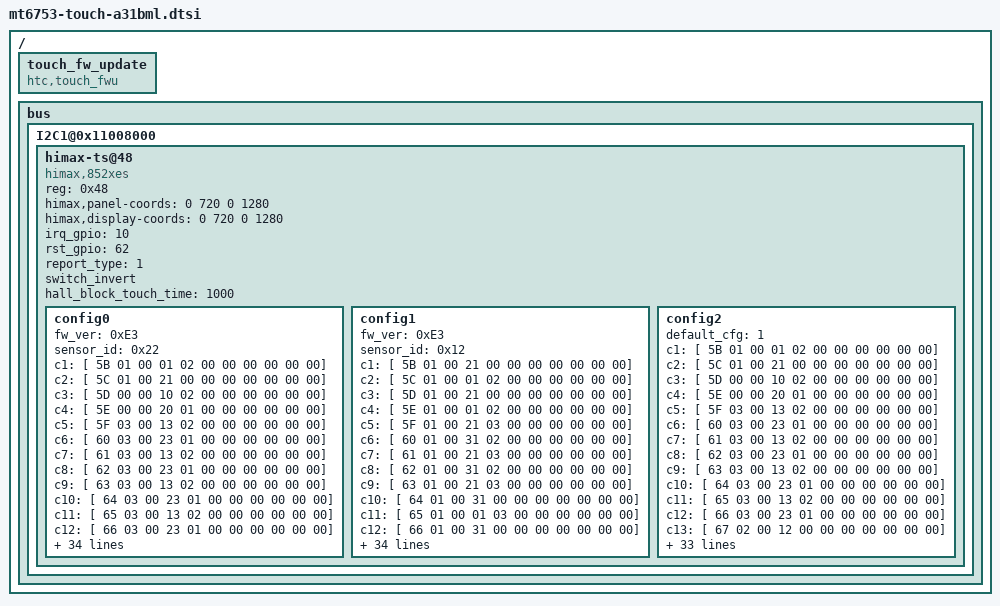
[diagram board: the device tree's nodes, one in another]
/{
	touch_fw_update {
		compatible = "htc,touch_fwu";
	};

	bus {
		I2C1@0x11008000 {

			status = "ok";
		himax-ts@48 {
			compatible               	= "himax,852xes";
			reg                      	= <0x48>;
				himax,panel-coords	= <0 720 0 1280>;
				himax,display-coords	= <0 720 0 1280>;
				irq_gpio = <10>;
				rst_gpio = <62>;
				report_type	= <1>;
				switch_invert;
				hall_block_touch_time	= <1000>;	/* msec */

			config0 {	//truly
				fw_ver     	= <0xE3>;
				sensor_id     	= <0x22>;
				c1 = [ 5B 01 00 01 02 00 00 00 00 00 00];
				c2 = [ 5C 01 00 21 00 00 00 00 00 00 00];
				c3 = [ 5D 00 00 10 02 00 00 00 00 00 00];
				c4 = [ 5E 00 00 20 01 00 00 00 00 00 00];
				c5 = [ 5F 03 00 13 02 00 00 00 00 00 00];
				c6 = [ 60 03 00 23 01 00 00 00 00 00 00];
				c7 = [ 61 03 00 13 02 00 00 00 00 00 00];
				c8 = [ 62 03 00 23 01 00 00 00 00 00 00];
				c9 = [ 63 03 00 13 02 00 00 00 00 00 00];
				c10 = [ 64 03 00 23 01 00 00 00 00 00 00];
				c11 = [ 65 03 00 13 02 00 00 00 00 00 00];
				c12 = [ 66 03 00 23 01 00 00 00 00 00 00];
				c13 = [ 67 02 00 12 00 00 00 00 00 00 00];
				c14 = [ 68 02 00 02 01 00 00 00 00 00 00];
				c15 = [ 69 02 00 12 00 00 00 00 00 00 00];
				c16 = [ 6A 02 00 02 00 00 00 00 00 00 00];
				c17 = [ 6B 02 00 02 00 00 00 00 00 00 00];
				c18 = [ D5 29 00 00 00 00 00 00 00 00 00 00 00 00 00 00 00];
				c19 = [ E1 08 01 01 01 02 03 0F 03 0F 03 0F 03 0F 08];
				c20 = [ BC 00 00 0C 00];
				c21 = [ C5 05 1E 00 10 1C 1A 0B 1E 02 1F];
				c22 = [ C6 19 10 1F];
				c23 = [ BD 00 0B];
				c24 = [ B9 01 15];
				c25 = [ EC 00 D8 8C];
				c26 = [ B0 00];
				c27 = [ DD 04];
				c28 = [ 42 02];
				c29 = [ CE 00];
				c30 = [ CA 00];
				c31 = [ 3F 00];
				c32 = [ EB 03];
				c33 = [ BA 00];
				c34 = [ BB 00];
				c35 = [ D3 06 01];
				c36 = [ 37 02 08 FF 08];
				c37 = [ A4 94 62 94 86];
				c38 = [ ED 00 04 0A 0A 04 00 00 00];
				c39 = [ CB 00 0F 0F FF FF 01 00 0F 00 32 00 FF 00];
				c40 = [ 40 01 5A
					   7F 01 70 10 04 00
					   50 10 0A 12 0A 0C 08 0C 0C 0C
					   32 28 50 80 20 00 00 00 00 00 00 00
					   94 0A F0 82 86 00
					   48 24 0F 0F 83 3C 00 00
					   11 00 41 42
					   18 38 00 12 00 00
					   10 01 1C 64 00 00
					   40 2F 2F 04 1F 00 00 00
					   04 06 24 08 08 00 00 00
					   A5 40 0A 00 10 9E 8D 20 00 02 03 10 00 00 00 A0
					   0F 42 60 A3 14 20 A0 C0
					   10 17 20 32 01 06 0B 00
					   A5 78 32 00
					   0D 17 A0 13
					   00 00 02 D0 05 00
					   00 00 00 00 3C 00 00 00 00 00 00 3A 2F 0A
					   00 00 00 00 3C 00 00 00 00 00 00 3A 2F 00
					   00 00 00 00 00 00 00 00];
				c41 = [ 40 0E 0D 25 24 23 22 21 20 1F 1E 1D 1C 1B 1A
					   19 FF FF 18 17 16 15 14 13 12 11 10 0F 0E 0D
					   00 01 02 03 04 FF FF FF FF 05 06 07 08 09 0A
					   0B 0C FF FF FF FF FF FF FF FF
					   1F 11 10 11 10 00
					   00 00 00 00 00 00
					   00 00 00 00 00 00
					   00 8F 00 00 00 00 00 00
					   11 C4 45 C5 48 5C 03 00 00 00
					   00 00 00 00 00 12];
			};

			config1 {	//
				fw_ver     	= <0xE3>;
				sensor_id     	= <0x12>;
				c1 = [ 5B 01 00 21 00 00 00 00 00 00 00];
                c2 = [ 5C 01 00 01 02 00 00 00 00 00 00];
                c3 = [ 5D 01 00 21 00 00 00 00 00 00 00];
                c4 = [ 5E 01 00 01 02 00 00 00 00 00 00];
                c5 = [ 5F 01 00 21 03 00 00 00 00 00 00];
                c6 = [ 60 01 00 31 02 00 00 00 00 00 00];
                c7 = [ 61 01 00 21 03 00 00 00 00 00 00];
                c8 = [ 62 01 00 31 02 00 00 00 00 00 00];
                c9 = [ 63 01 00 21 03 00 00 00 00 00 00];
                c10 = [ 64 01 00 31 00 00 00 00 00 00 00];
                c11 = [ 65 01 00 01 03 00 00 00 00 00 00];
                c12 = [ 66 01 00 31 00 00 00 00 00 00 00];
                c13 = [ 67 01 00 21 03 00 00 00 00 00 00];
                c14 = [ 68 01 00 01 02 00 00 00 00 00 00];
                c15 = [ 69 01 00 21 00 00 00 00 00 00 00];
                c16 = [ 6A 00 00 10 02 00 00 00 00 00 00];
                c17 = [ 6B 00 00 20 01 00 00 00 00 00 00];
                c18 = [ D5 29 00 00 00 00 00 00 00 00 00 00 00 00 00 00 00];
                c19 = [ E1 03 01 02 02 02 03 0F 03 0F 03 0F 03 0F 08];
                c20 = [ BC 00 00 00 00];
                c21 = [ C5 05 1F 00 10 19 1A 0B 1F 02 1F];
                c22 = [ C6 18 10 1E];
                c23 = [ BD 00 0B];
                c24 = [ B9 01 15];
                c25 = [ EC 10 D8 8C];
                c26 = [ B0 00];
                c27 = [ DD 03];
                c28 = [ 42 02];
                c29 = [ CE 00];
                c30 = [ CA 00];
                c31 = [ 3F 00];
                c32 = [ EB 03];
                c33 = [ BA 00];
                c34 = [ BB 00];
                c35 = [ D3 06 01];
                c36 = [ 37 21 08 FF 08];
                c37 = [ A4 94 62 94 86];
                c38 = [ ED 00 04 0A 0A 04 00 00 00];
                c39 = [ CB 00 0F 0F FF FF 01 00 0F 00 32 00 FF 00];
                c40 = [ 40 01 5A
                       5D 05 F0 14 04 00
                       1C 0C 0B 0C 08 08 08 0C 0C 0C
                       48 40 80 80 20 00 00 00 00 00 00 00
                       94 0A F0 82 86 00
                       48 24 0F 0F 83 3C 00 00
                       11 00 41 42
                       18 38 00 12 00 00
                       10 01 1C 64 00 00
                       18 3F 3F 02 1F 00 00 00
                       04 06 24 05 05 00 00 00
                       54 40 0A 54 10 D8 8C 20 00 02 03 10 00 00 00 A0
                       0F 02 60 A3 14 20 A0 C0
                       10 10 20 32 01 06 0B 00
                       A5 72 1D 00
                       0F 19 A0 13
                       00 00 02 D0 05 00
                       00 00 00 00 33 5B 00 00 00 00 00 35 4B 00
                       00 00 00 00 33 5B 00 00 00 00 00 35 4B 00
                       00 00 00 00 00 00 00 00];
                c41 = [ 40 0E 0D 0C 0B 0A 09 08 07 06 05 04 03 02
                       01 00 19 18 17 16 15 14 13 12 11 10 0F FF
                       FF FF 27 26 25 24 23 FF FF FF FF 22 21 20
                       1F 1E 1D 1C 1B 1A FF FF FF FF FF FF FF
                       1F 11 10 11 10 00
                       00 00 00 00 00 00
                       00 00 00 00 00 00
                       1A 7D 12 32 82 C2 05 00
                       11 C4 45 C5 48 5C 03 00 00 00
                       00 00 00 00 00 12];
			};

			config2 {	//default using truly
				default_cfg	= <1>;
				c1 = [ 5B 01 00 01 02 00 00 00 00 00 00];
				c2 = [ 5C 01 00 21 00 00 00 00 00 00 00];
				c3 = [ 5D 00 00 10 02 00 00 00 00 00 00];
				c4 = [ 5E 00 00 20 01 00 00 00 00 00 00];
				c5 = [ 5F 03 00 13 02 00 00 00 00 00 00];
				c6 = [ 60 03 00 23 01 00 00 00 00 00 00];
				c7 = [ 61 03 00 13 02 00 00 00 00 00 00];
				c8 = [ 62 03 00 23 01 00 00 00 00 00 00];
				c9 = [ 63 03 00 13 02 00 00 00 00 00 00];
				c10 = [ 64 03 00 23 01 00 00 00 00 00 00];
				c11 = [ 65 03 00 13 02 00 00 00 00 00 00];
				c12 = [ 66 03 00 23 01 00 00 00 00 00 00];
				c13 = [ 67 02 00 12 00 00 00 00 00 00 00];
				c14 = [ 68 02 00 02 01 00 00 00 00 00 00];
				c15 = [ 69 02 00 12 00 00 00 00 00 00 00];
				c16 = [ 6A 02 00 02 00 00 00 00 00 00 00];
				c17 = [ 6B 02 00 02 00 00 00 00 00 00 00];
				c18 = [ D5 29 00 00 00 00 00 00 00 00 00 00 00 00 00 00 00];
				c19 = [ E1 08 01 01 01 02 03 0F 03 0F 03 0F 03 0F 08];
				c20 = [ BC 00 00 0C 00];
				c21 = [ C5 05 1E 00 10 1C 1A 0B 1E 02 1F];
				c22 = [ C6 19 10 1F];
				c23 = [ BD 00 0B];
				c24 = [ B9 01 15];
				c25 = [ EC 00 D8 8C];
				c26 = [ B0 00];
				c27 = [ DD 04];
				c28 = [ 42 02];
				c29 = [ CE 00];
				c30 = [ CA 00];
				c31 = [ 3F 00];
				c32 = [ EB 03];
				c33 = [ BA 00];
				c34 = [ BB 00];
				c35 = [ D3 06 01];
				c36 = [ 37 02 08 FF 08];
				c37 = [ A4 94 62 94 86];
				c38 = [ ED 00 04 0A 0A 04 00 00 00];
				c39 = [ CB 00 0F 0F FF FF 01 00 0F 00 32 00 FF 00];
				c40 = [ 40 01 5A
					   7F 01 70 10 04 00
					   50 10 0A 12 0A 0C 08 0C 0C 0C
					   32 28 50 80 20 00 00 00 00 00 00 00
					   94 0A F0 82 86 00
					   48 24 0F 0F 83 3C 00 00
					   11 00 41 42
					   18 38 00 12 00 00
					   10 01 1C 64 00 00
					   40 2F 2F 04 1F 00 00 00
					   04 06 24 08 08 00 00 00
					   A5 40 0A 00 10 9E 8D 20 00 02 03 10 00 00 00 A0
					   0F 42 60 A3 14 20 A0 C0
					   10 17 20 32 01 06 0B 00
					   A5 78 32 00
					   0D 17 A0 13
					   00 00 02 D0 05 00
					   00 00 00 00 3C 00 00 00 00 00 00 3A 2F 0A
					   00 00 00 00 3C 00 00 00 00 00 00 3A 2F 00
					   00 00 00 00 00 00 00 00];
				c41 = [ 40 0E 0D 25 24 23 22 21 20 1F 1E 1D 1C 1B 1A
					   19 FF FF 18 17 16 15 14 13 12 11 10 0F 0E 0D
					   00 01 02 03 04 FF FF FF FF 05 06 07 08 09 0A
					   0B 0C FF FF FF FF FF FF FF FF
					   1F 11 10 11 10 00
					   00 00 00 00 00 00
			           00 00 00 00 00 00
					   00 8F 00 00 00 00 00 00
					   11 C4 45 C5 48 5C 03 00 00 00
					   00 00 00 00 00 12];
			};
			};
		};
	};
};
